# MSPM0C110X register map
Vendor: Texas Instruments; File version: This preliminary header file does not have a version number - build date: 2024-04-30 10:45:50
ARM Device
CPU: CM0 r0p1, little endian, MPU, no FPU, 3 interrupt priority bits
Registers are 32-bit, read-write, reset 0x0 unless marked. A register's access mark holds for its fields unless they carry their own. Offsets are from the block's base; lines under a group give offsets from that group; [hi:lo] are bit positions; {n}, {i} and the like mark numbered series; 'fields as' and 'values as' point back to an identical list; <NAME> marks a mode.

## Memory map
0x00000000 FLASH size 0x10000 — MEM
0x20000000 SYSMEM size 0x40000 — MEM
0x40004000 ADC0 size 0x2000 — PERIPHERALREGION
0x40030000 VREF size 0x1F00 — PERIPHERALREGION
0x40080000 WWDT0 size 0x1500 — WWDT
0x40084000 TIMG14 size 0x1F00 — PERIPHERALREGION
0x40090000 TIMG8 size 0x1F00 — PERIPHERALREGION
0x400A0000 GPIOA size 0x1F00 — PERIPHERALREGION
0x400AF000 SYSCTL size 0x3100
0x400C7000 DEBUGSS size 0x1F00 — DSSM
0x400C9000 EVENTLP size 0x3000 — PERIPHERALREGION
0x400CD000 FLASHCTL size 0x2000 — NVMNW_TINMAN
0x400F0000 I2C0 size 0x1F00 — PERIPHERALREGION
0x40108000 UART0 size 0x1F00 — PERIPHERALREGION
0x40400000 CPUSS size 0x1F00 — CPUSSMMR
0x40424000 WUC size 0x500 — PERIPHERALREGION
0x40428000 IOMUX size 0x2000 — PERIPHERALREGION
0x4042A000 DMA size 0x1F00 — PERIPHERALREGION
0x40440000 CRC size 0x2000 — PERIPHERALREGION
0x40468000 SPI0 size 0x1F00 — PERIPHERALREGION
0x4055A000 ADC0_SVT size 0x1000 — PERIPHERALREGIONSVT
0x40860000 TIMA0 size 0x1F00 — PERIPHERALREGION

## IOMUX — PERIPHERALREGION
Base 0x40428000
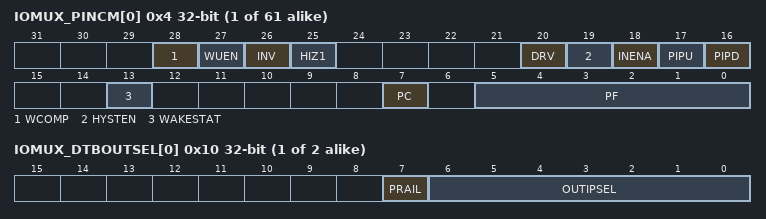
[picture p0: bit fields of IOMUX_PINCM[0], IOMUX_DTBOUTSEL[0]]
{0x4+4i} IOMUX_PINCM[{i}] (i=0..60) — Pin Control Management Register in SECCFG region
  [28] WCOMP — Wakeup Compare Value bit
    0=MATCH0 (Wakeup on a match of 0); 1=MATCH1 (Wakeup on a match of 1)
  [27] WUEN — Wakeup Enable bit
    0=DISABLE (wakeup is disabled.); 1=ENABLE (wakeup is enabled)
  [26] INV — Data inversion selection
    0=DISABLE (Data inversion is disabled.); 1=ENABLE (Data inversion is enabled)
  [25] HIZ1 — High output value will tri-state the output when this bit is enabled
    0=DISABLE (open-drain is disabled.); 1=ENABLE (open-drain is enabled.)
  [20] DRV — Drive strength control selection, for HS IOCELL only
    0=DRVVAL0 (Drive setting of 0 selected); 1=DRVVAL1 (Drive setting of 1 selected)
  [19] HYSTEN — Hysteresis Enable Control Selection
    0=DISABLE (hysteresis is disabled.); 1=ENABLE (hysteresis is enabled)
  [18] INENA — Input Enable Control Selection
    0=DISABLE (Input enable is disabled.); 1=ENABLE (Input enable is enabled.)
  [17] PIPU — Pull Up control selection
    0=DISABLE (Pull up is disabled.); 1=ENABLE (Pull up is enabled)
  [16] PIPD — Pull Down control selection
    0=DISABLE (Pull down is disabled.); 1=ENABLE (Pull down is enabled)
  [13] WAKESTAT ro — This has the IOPAD WAKEUP signal as status bit.
    0=DISABLE (wakeup source is NOT from this IOCELL); 1=ENABLE (wakeup source is from this IOCELL)
  [7] PC — Peripheral is Connected
    0=UNCONNECTED (The output of the peripheral (and its output enable) will not propagate to the IOCELL); 1=CONNECTED (The output latch of the dataflow will be transparent)
  [5:0] PF — Peripheral Function selection bits
{0x1900+0xC0*i} IOMUX_LMGMT_DFT_ATRT[{i}] (i=0..0) group
  0x00 IOMUX_DTBENA — DTB ENA Register
    [31:0] ENABLE — DTB Enable
      0=DISABLE (Disable DTB output); 1=ENABLE (Enable DTB output)
  0x0C IOMUX_DTBBUSSEL — DTBBUSSEL Register
    [31:0] SEL — DTB bus selector
      0=MIN (DTB bus 0 is selected); 0xFFFFFFFF=MAX (dtb bus 0xffffffff is selected)
  {0x10+4j} IOMUX_DTBOUTSEL[{j}] (j=0..1) — DTBOUSEL Register
    [7] PRAIL — PRAIL bit to identify the Power Rail of the selected IP.
      0=SVTSEL (Selected IP is SVT); 1=ULLSEL (Selected IP is ULL)
    [6:0] OUTIPSEL — Select bits to configure the output IP for the selected DTB Lane.
  {0x90+4j} IOMUX_DTBDIR[{j}] (j=0..1) — DTBDIR Register
    [5:0] DIR — DTB lane direction bit, 0: DTB OUTPUT enable, 1: DTB INPUT enable
      0=OUT (DTN lane direction is output, from core to PAD); 1=IN (DTN lane direction is input, from PAD to core)
  {0xB0+4j} IOMUX_IOTBEN{j} (j=0..3) — IOTB ENA Register{j}
    [31:0] SIG{32j+32} — IOTB Enable Bit for SIG{32j+1}-{32j+32}
      0=DISABLE (Disable IOTB); 0xFFFFFFFF=ENABLE (Enable IOTB)

## Licence text in the file
Copyright (C) 2024 Texas Instruments Incorporated - http://www.ti.com/ Redistribution and use in source and binary forms, with or without modification, are permitted provided that the following conditions are met: Redistributions of source code must retain the above copyright notice, this list of conditions and the following disclaimer. Redistributions in binary form must reproduce the above copyright notice, this list of conditions and the following disclaimer in the documentation and/or other materials provided with the distribution. Neither the name of Texas Instruments Incorporated nor the names of its contributors may be used to endorse or promote products derived from this software without specific prior written permission. THIS SOFTWARE IS PROVIDED BY THE COPYRIGHT HOLDERS AND CONTRIBUTORS "AS IS" AND ANY EXPRESS OR IMPLIED WARRANTIES, INCLUDING, BUT NOT LIMITED TO, THE IMPLIED WARRANTIES OF MERCHANTABILITY AND FITNESS FOR A PARTICULAR PURPOSE ARE DISCLAIMED. IN NO EVENT SHALL THE COPYRIGHT OWNER OR CONTRIBUTORS BE LIABLE FOR ANY DIRECT, INDIRECT, INCIDENTAL, SPECIAL, EXEMPLARY, OR CONSEQUENTIAL DAMAGES (INCLUDING, BUT NOT LIMITED TO, PROCUREMENT OF SUBSTITUTE GOODS OR SERVICES; LOSS OF USE, DATA, OR PROFITS; OR BUSINESS INTERRUPTION) HOWEVER CAUSED AND ON ANY THEORY OF LIABILITY, WHETHER IN CONTRACT, STRICT LIABILITY, OR TORT (INCLUDING NEGLIGENCE OR OTHERWISE) ARISING IN ANY WAY OUT OF THE USE OF THIS SOFTWARE, EVEN IF ADVISED OF THE POSSIBILITY OF SUCH DAMAGE.
